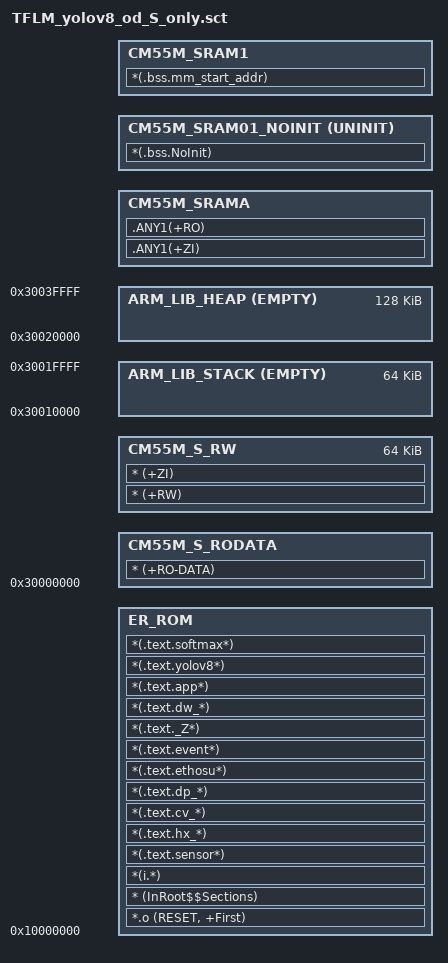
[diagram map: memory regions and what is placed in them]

#include "WE2_device_addr.h"

/*--------------------- Flash Configuration ----------------------------------*/
#define CM55M_ROM_BASE     0x10000000
#define CM55M_ROM_SIZE     0x00040000

/*--------------------- Embedded RAM Configuration ---------------------------*/
#define CM55M_DATA_BASE     0x30000000
#define CM55M_DATA_SIZE     0x00040000

#define CM55M_SRAM_START	0x34000000

/*comment here, we load bss section at start, so SRAM_BASE can be 0 */
#define CM55M_SRAM_BASE     BOOT2NDLOADER_BASE
#define CM55M_SRAM_SIZE     0x00200000-(CM55M_SRAM_BASE-CM55M_SRAM_START) 

/*--------------------- Stack / Heap Configuration ---------------------------*/
#define __STACK_SIZE    0x00010000
#define __HEAP_SIZE     0x00020000
#define CM55M_APP_DATASECT_SIZE  (CM55M_DATA_SIZE - __STACK_SIZE - __HEAP_SIZE)
#define CM55M_APP_SRAMSECT_SIZE  (CM55M_SRAM0_SIZE - __STACK_SIZE - __HEAP_SIZE)
#define EXTRA_BASE     CM55M_DATA_BASE
#define EXTRA_SIZE     CM55M_APP_DATASECT_SIZE
#define __STACK_LIMIT   (EXTRA_BASE + EXTRA_SIZE)
#define __STACK_BASE    (EXTRA_BASE + EXTRA_SIZE + __STACK_SIZE)
#define __HEAP_BASE     (EXTRA_BASE + EXTRA_SIZE + __STACK_SIZE)
#define __HEAP_LIMIT    (EXTRA_BASE + EXTRA_SIZE + __STACK_SIZE + __HEAP_SIZE)

LR_ROM1 CM55M_ROM_BASE CM55M_ROM_SIZE  {                       
  ER_ROM +0 {                                       
   *.o (RESET, +First)
   * (InRoot$$Sections)
   //.ANY2(+RO)
   //*(.text*)
   *(i.*)
   *(.text.sensor*)
   *(.text.hx_*)
   *(.text.cv_*)
   *(.text.dp_*)
   *(.text.ethosu*)
   *(.text.event*)
   *(.text._Z*)
   *(.text.dw_*)
   *(.text.app*)
   *(.text.yolov8*)
   *(.text.softmax*)
  }
}

LR_ROM2 CM55M_DATA_BASE  CM55M_DATA_SIZE{   
  CM55M_S_RODATA  +0 { 
   * (+RO-DATA)
  }	 
  CM55M_S_RW +0 CM55M_APP_DATASECT_SIZE{    
   * (+RW)
   * (+ZI)  
 
  }


  ARM_LIB_STACK __STACK_BASE ALIGN 8 EMPTY -__STACK_SIZE {  
  }
  
  ARM_LIB_HEAP  __HEAP_BASE ALIGN 8 EMPTY __HEAP_SIZE  { 
  }
}

LR_ROM3 CM55M_SRAM_BASE  CM55M_SRAM_SIZE{
  CM55M_SRAMA +0 {
	.ANY1(+ZI)
	.ANY1(+RO)
  }
  CM55M_SRAM01_NOINIT +0 UNINIT{  
    *(.bss.NoInit)
  }
  CM55M_SRAM1 +0{ 
    *(.bss.mm_start_addr)
  }

}

